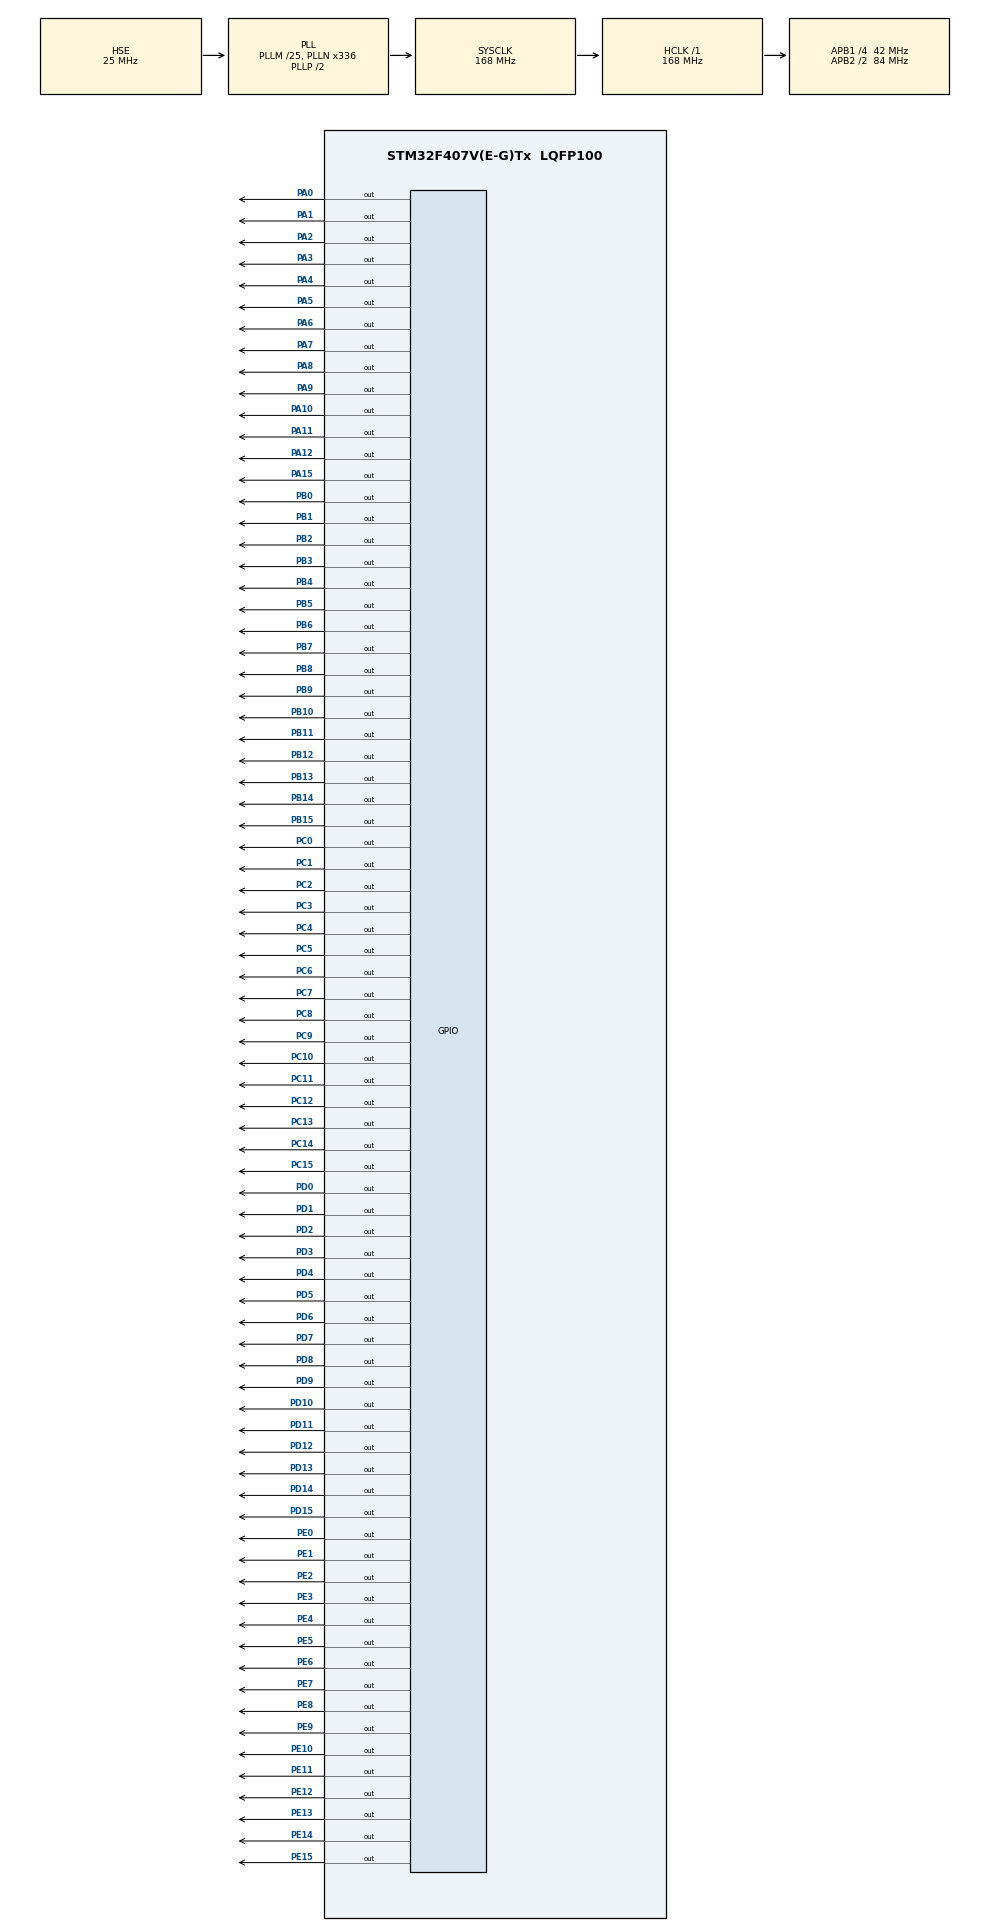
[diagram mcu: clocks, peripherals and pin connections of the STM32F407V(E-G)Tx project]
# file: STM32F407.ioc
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Mcu.Family=STM32F4
Mcu.Name=STM32F407V(E-G)Tx
Mcu.Package=LQFP100
NVIC.PriorityGroup=NVIC_PRIORITYGROUP_4
PA0-WKUP.Signal=GPIO_Output
PA1.Signal=GPIO_Output
PA10.Signal=GPIO_Output
PA11.Signal=GPIO_Output
PA12.Signal=GPIO_Output
PA13.Mode=Serial_Wire
PA13.Signal=SYS_JTMS-SWDIO
PA14.Mode=Serial_Wire
PA14.Signal=SYS_JTCK-SWCLK
PA15.Signal=GPIO_Output
PA2.Signal=GPIO_Output
PA3.Signal=GPIO_Output
PA4.Signal=GPIO_Output
PA5.Signal=GPIO_Output
PA6.Signal=GPIO_Output
PA7.Signal=GPIO_Output
PA8.Signal=GPIO_Output
PA9.Signal=GPIO_Output
PB0.Signal=GPIO_Output
PB1.Signal=GPIO_Output
PB10.Signal=GPIO_Output
PB11.Signal=GPIO_Output
PB12.Signal=GPIO_Output
PB13.Signal=GPIO_Output
PB14.Signal=GPIO_Output
PB15.Signal=GPIO_Output
PB2.Signal=GPIO_Output
PB3.Signal=GPIO_Output
PB4.Signal=GPIO_Output
PB5.Signal=GPIO_Output
PB6.Signal=GPIO_Output
PB7.Signal=GPIO_Output
PB8.Signal=GPIO_Output
PB9.Signal=GPIO_Output
PC0.Signal=GPIO_Output
PC1.Signal=GPIO_Output
PC10.Signal=GPIO_Output
PC11.Signal=GPIO_Output
PC12.Signal=GPIO_Output
PC13-ANTI_TAMP.Signal=GPIO_Output
PC14-OSC32_IN.Signal=GPIO_Output
PC15-OSC32_OUT.Signal=GPIO_Output
PC2.Signal=GPIO_Output
PC3.Signal=GPIO_Output
PC4.Signal=GPIO_Output
PC5.Signal=GPIO_Output
PC6.Signal=GPIO_Output
PC7.Signal=GPIO_Output
PC8.Signal=GPIO_Output
PC9.Signal=GPIO_Output
PD0.Signal=GPIO_Output
PD1.Signal=GPIO_Output
PD10.Signal=GPIO_Output
PD11.Signal=GPIO_Output
PD12.Signal=GPIO_Output
PD13.Signal=GPIO_Output
PD14.Signal=GPIO_Output
PD15.Signal=GPIO_Output
PD2.Signal=GPIO_Output
PD3.Signal=GPIO_Output
PD4.Signal=GPIO_Output
PD5.Signal=GPIO_Output
PD6.Signal=GPIO_Output
PD7.Signal=GPIO_Output
PD8.Signal=GPIO_Output
PD9.Signal=GPIO_Output
PE0.Signal=GPIO_Output
PE1.Signal=GPIO_Output
PE10.Signal=GPIO_Output
PE11.Signal=GPIO_Output
PE12.Signal=GPIO_Output
PE13.Signal=GPIO_Output
PE14.Signal=GPIO_Output
PE15.Signal=GPIO_Output
PE2.Signal=GPIO_Output
PE3.Signal=GPIO_Output
PE4.Signal=GPIO_Output
PE5.Signal=GPIO_Output
PE6.Signal=GPIO_Output
PE7.Signal=GPIO_Output
PE8.Signal=GPIO_Output
PE9.Signal=GPIO_Output
PH0-OSC_IN.Mode=HSE-External-Oscillator
PH0-OSC_IN.Signal=RCC_OSC_IN
PH1-OSC_OUT.Mode=HSE-External-Oscillator
PH1-OSC_OUT.Signal=RCC_OSC_OUT
ProjectManager.HeapSize=0x1000
ProjectManager.StackSize=0x1000
ProjectManager.TargetToolchain=MDK-ARM V5.32
RCC.48MHZClocksFreq_Value=48000000
RCC.AHBFreq_Value=168000000
RCC.APB1CLKDivider=RCC_HCLK_DIV4
RCC.APB1Freq_Value=42000000
RCC.APB1TimFreq_Value=84000000
RCC.APB2CLKDivider=RCC_HCLK_DIV2
RCC.APB2Freq_Value=84000000
RCC.APB2TimFreq_Value=168000000
RCC.CortexFreq_Value=168000000
RCC.HCLKFreq_Value=168000000
RCC.HSE_VALUE=25000000
RCC.HSI_VALUE=16000000
RCC.LSE_VALUE=32768
RCC.PLLM=25
RCC.PLLN=336
RCC.PLLQ=7
RCC.PLLSourceVirtual=RCC_PLLSOURCE_HSE
RCC.SYSCLKFreq_VALUE=168000000
RCC.SYSCLKSource=RCC_SYSCLKSOURCE_PLLCLK
RCC.VCOOutputFreq_Value=336000000
board=custom

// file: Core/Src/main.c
/* USER CODE BEGIN Header */
/**==================================================================================================================
 ** 【代码编写】  魔女开发板团队
 ** 【淘    宝】  魔女开发板       https://demoboard.taobao.com
 **==================================================================================================================
 ** 【实验名称】  GPIO 全引脚电平翻转测试
 **
 ** 【适用平台】  STM32F407 + Keil5 + HAL库
 **
 ** 【功能概述】  本程序用于测试开发板 GPIO 引脚的基本输出功能，通过周期性翻转所有 GPIO 引脚电平。
 **               1. 初始化系统时钟及 GPIO（所有已使能的 GPIO 端口）
 **               2. 主循环中每隔 1 秒翻转一次 GPIOA、GPIOB、GPIOC、GPIOD、GPIOE 的所有引脚电平
 **               3. 可用于验证硬件连接、观察引脚波形或快速测试开发板
 **
 ** 【硬件注意】  1. 本程序会同时翻转多个 GPIO 端口的全部引脚，请确保外接设备不会因电平变化而损坏
 **               2. 若某些引脚用于特殊功能（如 JTAG/SWD），需先禁用相应功能或注意不影响调试
 **               3. 建议使用示波器或逻辑分析仪观察引脚输出波形
 **
 ** 【移植说明】  1. 本工程无需额外外设驱动文件，仅需 HAL 库支持
 **               2. 如需测试特定引脚，可修改 HAL_GPIO_TogglePin 中的端口及引脚宏
 **               3. 延时时间可通过修改 HAL_Delay 参数调整
 **
 ** 【使用说明】  1. 编译下载后，开发板所有 GPIO 引脚将每秒同步翻转一次
 **               2. 可用万用表或示波器测量任意引脚，观察电平周期性变化
 **               3. 该程序常用于验证最小系统是否正常工作，或排查引脚虚焊问题
 **
 ** 【调试建议】  1. 若程序无法运行，检查系统时钟配置及 HAL 初始化
 **               2. 若某引脚无输出，检查该引脚对应的 GPIO 时钟是否已使能（CubeMX 已自动处理）
 **               3. 注意避免引脚冲突（如与调试接口共用）
 **
 ** 【更新记录】  2025-03-27  创建 GPIO 全引脚翻转测试程序
 **
 ** 【备注说明】  版权归魔女科技所有，仅供学习使用，请勿用于商业用途。
 **               https://demoboard.taobao.com
 **
==================================================================================================================**/
/* USER CODE END Header */
#include "main.h"
#include "gpio.h"

/* USER CODE BEGIN Includes */
// 所用用户代码，必须写在配对的BEGIN与END注释之间，否则重新生成时会被自动删除

/* USER CODE END Includes */

void SystemClock_Config(void);

int main(void)
{

    /* MCU Configuration--------------------------------------------------------*/

    /* Reset of all peripherals, Initializes the Flash interface and the Systick. */
    HAL_Init();

    /* Configure the system clock */
    SystemClock_Config();

    /* Initialize all configured peripherals */
    MX_GPIO_Init();
    /* USER CODE BEGIN 2 */
    // 用户代码，必须写在配对的BEGIN与END注释之间; 否则,重新生成时会被自动删除;

    /* USER CODE END 2 */

    /* Infinite loop */
    while (1)
    {

        /* USER CODE BEGIN 3 */
        // 用户代码，必须写在配对的BEGIN与END注释之间; 否则,重新生成时会被自动删除;

        HAL_Delay(1000);                            // 延时函数，参数：ms; 注意：CubeMX生成的HAL_Delay(), 函数内部为避免无效操作，会对传入参数+1，因此，如果只需要几ms延时建议传入参数时-1，如果需要大几百ms的非精准延时，那参数不-1也影响不大

        HAL_GPIO_TogglePin(GPIOA, GPIO_PIN_All);    // 反转 GPIOA 引脚的电平
        HAL_GPIO_TogglePin(GPIOB, GPIO_PIN_All);    // 反转 GPIOB 引脚的电平
        HAL_GPIO_TogglePin(GPIOC, GPIO_PIN_All);    // 反转 GPIOC 引脚的电平
        HAL_GPIO_TogglePin(GPIOD, GPIO_PIN_All);    // 反转 GPIOD 引脚的电平
        HAL_GPIO_TogglePin(GPIOE, GPIO_PIN_All);    // 反转 GPIOE 引脚的电平

    }
    /* USER CODE END 3 */
}

void SystemClock_Config(void)
{
    RCC_OscInitTypeDef RCC_OscInitStruct = {0};
    RCC_ClkInitTypeDef RCC_ClkInitStruct = {0};

    /** Configure the main internal regulator output voltage
    */
    __HAL_RCC_PWR_CLK_ENABLE();
    __HAL_PWR_VOLTAGESCALING_CONFIG(PWR_REGULATOR_VOLTAGE_SCALE1);

    /** Initializes the RCC Oscillators according to the specified parameters
    * in the RCC_OscInitTypeDef structure.
    */
    RCC_OscInitStruct.OscillatorType = RCC_OSCILLATORTYPE_HSE;
    RCC_OscInitStruct.HSEState = RCC_HSE_ON;
    RCC_OscInitStruct.PLL.PLLState = RCC_PLL_ON;
    RCC_OscInitStruct.PLL.PLLSource = RCC_PLLSOURCE_HSE;
    RCC_OscInitStruct.PLL.PLLM = 25;
    RCC_OscInitStruct.PLL.PLLN = 336;
    RCC_OscInitStruct.PLL.PLLP = RCC_PLLP_DIV2;
    RCC_OscInitStruct.PLL.PLLQ = 7;
    if (HAL_RCC_OscConfig(&RCC_OscInitStruct) != HAL_OK)
    {
        Error_Handler();
    }

    /** Initializes the CPU, AHB and APB buses clocks
    */
    RCC_ClkInitStruct.ClockType = RCC_CLOCKTYPE_HCLK | RCC_CLOCKTYPE_SYSCLK
                                  | RCC_CLOCKTYPE_PCLK1 | RCC_CLOCKTYPE_PCLK2;
    RCC_ClkInitStruct.SYSCLKSource = RCC_SYSCLKSOURCE_PLLCLK;
    RCC_ClkInitStruct.AHBCLKDivider = RCC_SYSCLK_DIV1;
    RCC_ClkInitStruct.APB1CLKDivider = RCC_HCLK_DIV4;
    RCC_ClkInitStruct.APB2CLKDivider = RCC_HCLK_DIV2;

    if (HAL_RCC_ClockConfig(&RCC_ClkInitStruct, FLASH_LATENCY_5) != HAL_OK)
    {
        Error_Handler();
    }
}

/* USER CODE BEGIN 4 */
/* 所有用户代码，必须写在配对的BEGIN与END注释行之间，否则重新生成时会被删除 */

/* USER CODE END 4 */

void Error_Handler(void)
{
    __disable_irq();
    while (1)
    {
    }
}
